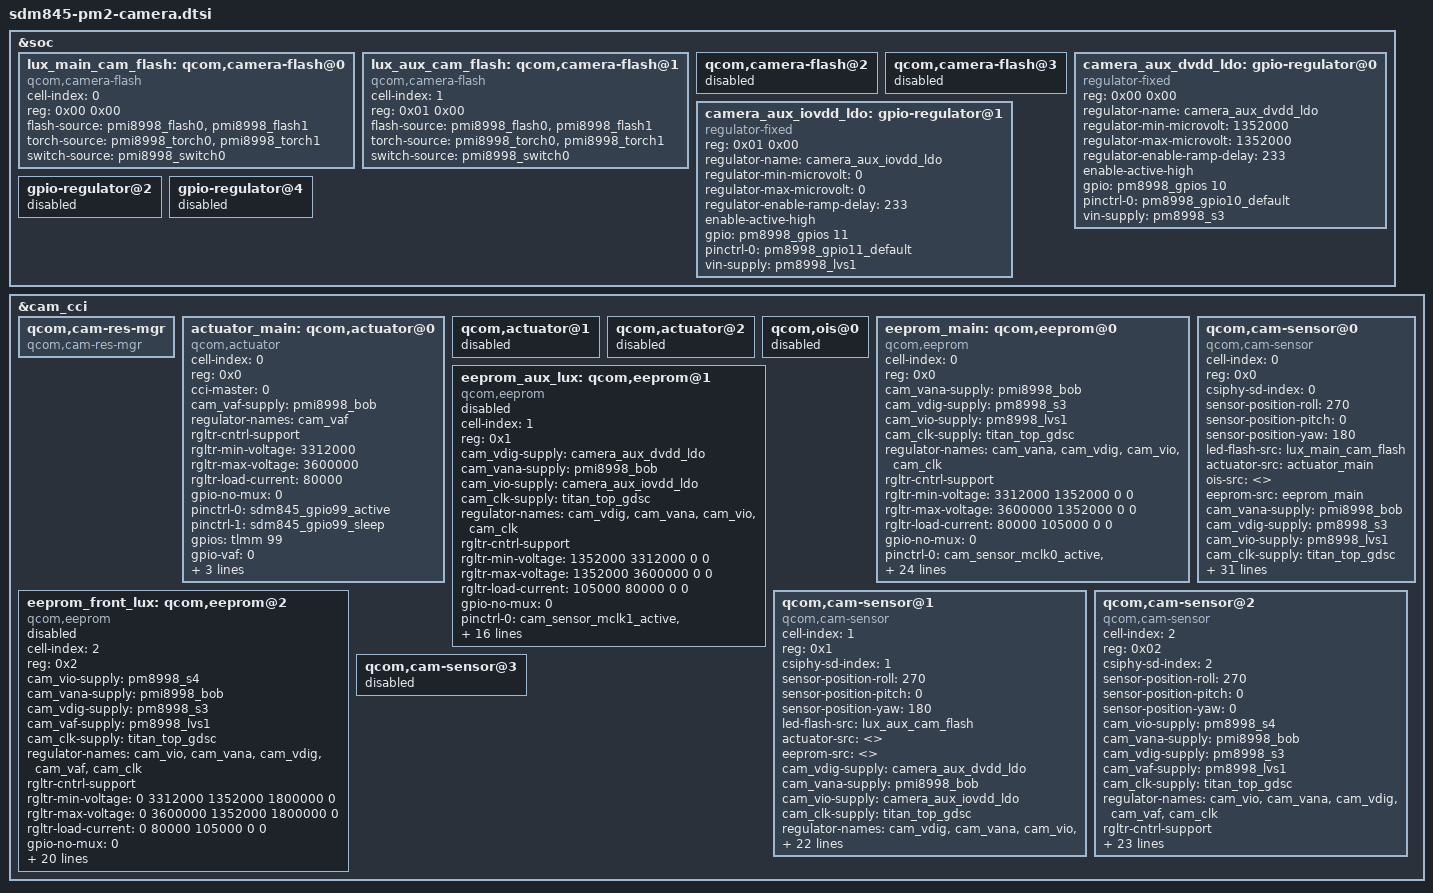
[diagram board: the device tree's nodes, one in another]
/*
 * Copyright (c) 2016-2018, The Linux Foundation. All rights reserved.
 *
 * This program is free software; you can redistribute it and/or modify
 * it under the terms of the GNU General Public License version 2 and
 * only version 2 as published by the Free Software Foundation.
 *
 * This program is distributed in the hope that it will be useful,
 * but WITHOUT ANY WARRANTY; without even the implied warranty of
 * MERCHANTABILITY or FITNESS FOR A PARTICULAR PURPOSE.  See the
 * GNU General Public License for more details.
 */

&soc {
	lux_main_cam_flash: qcom,camera-flash@0 {
		cell-index = <0>;
		reg = <0x00 0x00>;
		compatible = "qcom,camera-flash";
		flash-source = <&pmi8998_flash0 &pmi8998_flash1>;
		torch-source = <&pmi8998_torch0 &pmi8998_torch1>;
		switch-source = <&pmi8998_switch0>;
		status = "ok";
	};

	lux_aux_cam_flash: qcom,camera-flash@1 {
		cell-index = <1>;
		reg = <0x01 0x00>;
		compatible = "qcom,camera-flash";
		flash-source = <&pmi8998_flash0 &pmi8998_flash1>;
		torch-source = <&pmi8998_torch0 &pmi8998_torch1>;
		switch-source = <&pmi8998_switch0>;
		status = "ok";
	};

	qcom,camera-flash@2 {
		status = "disabled";
	};

	qcom,camera-flash@3 {
		status = "disabled";
	};

	camera_aux_dvdd_ldo: gpio-regulator@0 {
		compatible = "regulator-fixed";
		reg = <0x00 0x00>;
		regulator-name = "camera_aux_dvdd_ldo";
		regulator-min-microvolt = <1352000>;
		regulator-max-microvolt = <1352000>;
		regulator-enable-ramp-delay = <233>;
		enable-active-high;
		gpio = <&pm8998_gpios 10 0>;
		pinctrl-names = "default";
		pinctrl-0 = <&pm8998_gpio10_default>;
		vin-supply = <&pm8998_s3>;
	};

	camera_aux_iovdd_ldo: gpio-regulator@1 {
		compatible = "regulator-fixed";
		reg = <0x01 0x00>;
		regulator-name = "camera_aux_iovdd_ldo";
		regulator-min-microvolt = <0>;
		regulator-max-microvolt = <0>;
		regulator-enable-ramp-delay = <233>;
		enable-active-high;
		gpio = <&pm8998_gpios 11 0>;
		pinctrl-names = "default";
		pinctrl-0 = <&pm8998_gpio11_default>;
		vin-supply = <&pm8998_lvs1>; /*use for i2c pull up*/
	};

	gpio-regulator@2 {
		status = "disabled";
	};

	gpio-regulator@4 {
		status = "disabled";
	};
};

&cam_cci {
	qcom,cam-res-mgr {
		compatible = "qcom,cam-res-mgr";
		status = "ok";
	};

	actuator_main: qcom,actuator@0 {
		cell-index = <0>;
		reg = <0x0>;
		compatible = "qcom,actuator";
		cci-master = <0>;
		cam_vaf-supply = <&pmi8998_bob>;
		regulator-names = "cam_vaf";
		rgltr-cntrl-support;
		rgltr-min-voltage = <3312000>;
		rgltr-max-voltage = <3600000>;
		rgltr-load-current = <80000>;
		gpio-no-mux = <0>;
		pinctrl-names = "cam_default", "cam_suspend";
		pinctrl-0 = <&sdm845_gpio99_active>;
		pinctrl-1 = <&sdm845_gpio99_sleep>;
		gpios = <&tlmm 99 0>;
		gpio-vaf = <0>;
		gpio-req-tbl-num = <0>;
		gpio-req-tbl-flags = <0>;
		gpio-req-tbl-label = "CAM_VAF0";
	};

	qcom,actuator@1 {
		status = "disabled";
	};

	qcom,actuator@2 {
		status = "disabled";
	};

	qcom,ois@0 {
		status = "disabled";
	};

	eeprom_main: qcom,eeprom@0 {
		cell-index = <0>;
		reg = <0x0>;
		compatible = "qcom,eeprom";
		cam_vana-supply = <&pmi8998_bob>;
		cam_vdig-supply = <&pm8998_s3>;
		cam_vio-supply = <&pm8998_lvs1>; /* for i2c pull-up voltage */
		cam_clk-supply = <&titan_top_gdsc>;
		regulator-names = "cam_vana", "cam_vdig", "cam_vio",
			"cam_clk";
		rgltr-cntrl-support;
		rgltr-min-voltage = <3312000 1352000 0 0>;
		rgltr-max-voltage = <3600000 1352000 0 0>;
		rgltr-load-current = <80000 105000 0 0>;
		gpio-no-mux = <0>;
		pinctrl-names = "cam_default", "cam_suspend";
		pinctrl-0 = <&cam_sensor_mclk0_active
				&sdm845_gpio30_active
				&sdm845_gpio100_active
				&sdm845_gpio91_active
				&sdm845_gpio25_active
				&sdm845_gpio51_active>;
		pinctrl-1 = <&cam_sensor_mclk0_suspend
				&sdm845_gpio30_sleep
				&sdm845_gpio100_sleep
				&sdm845_gpio91_sleep
				&sdm845_gpio25_sleep
				&sdm845_gpio51_sleep>;
		gpios = <&tlmm 13 0>,
			<&tlmm 30 0>,
			<&tlmm 100 0>,
			<&tlmm 91 0>,
			<&tlmm 25 0>,
			<&tlmm 51 0>;
		gpio-reset = <1>;
		gpio-vana = <2>;
		gpio-vdig = <3>;
		gpio-vio = <4>;
		gpio-custom1 = <5>;
		gpio-req-tbl-num = <0 1 2 3 4 5>;
		gpio-req-tbl-flags = <1 0 0 0 0 0>;
		gpio-req-tbl-label = "CAMIF_MCLK0",
					"CAM_RESET0",
					"CAM_VANA0",
					"CAM_VDIG0",
					"CAM_VIO0",
					"CAM_CUSTOM0";
		sensor-position = <0>;
		sensor-mode = <0>;
		cci-master = <0>;
		status = "ok";
		clocks = <&clock_camcc CAM_CC_MCLK0_CLK>;
		clock-names = "cam_clk";
		clock-cntl-level = "turbo";
		clock-rates = <24000000>;
	};

	eeprom_aux_lux: qcom,eeprom@1 {
		cell-index = <1>;
		reg = <0x1>;
		compatible = "qcom,eeprom";
		cam_vdig-supply = <&camera_aux_dvdd_ldo>;
		cam_vana-supply = <&pmi8998_bob>;
		cam_vio-supply = <&camera_aux_iovdd_ldo>;
		cam_clk-supply = <&titan_top_gdsc>;
		regulator-names = "cam_vdig", "cam_vana", "cam_vio", "cam_clk";
		rgltr-cntrl-support;
		rgltr-min-voltage = <1352000 3312000 0 0>;
		rgltr-max-voltage = <1352000 3600000 0 0>;
		rgltr-load-current = <105000 80000 0 0>;
		gpio-no-mux = <0>;
		pinctrl-names = "cam_default", "cam_suspend";
		pinctrl-0 = <&cam_sensor_mclk1_active
				&sdm845_gpio80_active>;
		pinctrl-1 = <&cam_sensor_mclk1_suspend
				&sdm845_gpio80_sleep>;
		gpios = <&tlmm 14 0>,
			<&tlmm 80 0>,
			<&pm8998_gpios 12 0>;
		gpio-reset = <1>;
		gpio-vana = <2>;
		gpio-req-tbl-num = <0 1 2>;
		gpio-req-tbl-flags = <1 0 0>;
		gpio-req-tbl-label = "CAMIF_MCLK1",
					"CAM_RESET1",
					"CAM_VANA1";
		sensor-position = <0>;
		sensor-mode = <0>;
		cci-master = <1>;
		status = "disabled";
		clocks = <&clock_camcc CAM_CC_MCLK1_CLK>;
		clock-names = "cam_clk";
		clock-cntl-level = "turbo";
		clock-rates = <23076923>;
	};

	eeprom_front_lux: qcom,eeprom@2 {
		cell-index = <2>;
		reg = <0x2>;
		compatible = "qcom,eeprom";
		cam_vio-supply = <&pm8998_s4>;
		cam_vana-supply = <&pmi8998_bob>;
		cam_vdig-supply = <&pm8998_s3>;
		cam_vaf-supply = <&pm8998_lvs1>;
		cam_clk-supply = <&titan_top_gdsc>;
		regulator-names = "cam_vio", "cam_vana", "cam_vdig","cam_vaf",
			"cam_clk";
		rgltr-cntrl-support;
		rgltr-min-voltage = <0 3312000 1352000 1800000 0>;
		rgltr-max-voltage = <0 3600000 1352000 1800000 0>;
		rgltr-load-current = <0 80000 105000 0 0>;
		gpio-no-mux = <0>;
		pinctrl-names = "cam_default", "cam_suspend";
		pinctrl-0 = <&cam_sensor_mclk2_active
				 &sdm845_gpio9_active>;
		pinctrl-1 = <&cam_sensor_mclk2_suspend
				 &sdm845_gpio9_sleep>;
		gpios = <&tlmm 15 0>,
			<&tlmm 9 0>,
			<&pm8998_gpios 7 0>,
			<&pm8998_gpios 8 0>,
			<&pm8998_gpios 4 0>;
		gpio-reset = <1>;
		gpio-vana = <2>;
		gpio-vio = <3>;
		gpio-vdig = <4>;
		gpio-req-tbl-num = <0 1 2 3 4>;
		gpio-req-tbl-flags = <1 0 0 0 0>;
		gpio-req-tbl-label = "CAMIF_MCLK2",
					"CAM_RESET2",
					"CAM_VANA2",
					"CAM_VIO2",
					"CAM_VDIG2";
		sensor-position = <1>;
		sensor-mode = <0>;
		cci-master = <1>;
		status = "disabled";
		clocks = <&clock_camcc CAM_CC_MCLK2_CLK>;
		clock-names = "cam_clk";
		clock-cntl-level = "turbo";
		clock-rates = <24000000>;
	};

	qcom,cam-sensor@0 {
		cell-index = <0>;
		compatible = "qcom,cam-sensor";
		reg = <0x0>;
		csiphy-sd-index = <0>;
		sensor-position-roll = <270>;
		sensor-position-pitch = <0>;
		sensor-position-yaw = <180>;
		led-flash-src = <&lux_main_cam_flash>;
		actuator-src = <&actuator_main>;
		ois-src = <>;
		eeprom-src = <&eeprom_main>;
		cam_vana-supply = <&pmi8998_bob>;
		cam_vdig-supply = <&pm8998_s3>;
		cam_vio-supply = <&pm8998_lvs1>; /* for i2c pull-up voltage */
		cam_clk-supply = <&titan_top_gdsc>;
		regulator-names = "cam_vana", "cam_vdig", "cam_vio",
			"cam_clk";
		rgltr-cntrl-support;
		rgltr-min-voltage = <3312000 1352000 0 0>;
		rgltr-max-voltage = <3600000 1352000 0 0>;
		rgltr-load-current = <80000 105000 0 0>;
		gpio-no-mux = <0>;
		pinctrl-names = "cam_default", "cam_suspend";
		pinctrl-0 = <&cam_sensor_mclk0_active
				&sdm845_gpio30_active
				&sdm845_gpio100_active
				&sdm845_gpio91_active
				&sdm845_gpio25_active
				&sdm845_gpio51_active>;
		pinctrl-1 = <&cam_sensor_mclk0_suspend
				&sdm845_gpio30_sleep
				&sdm845_gpio100_sleep
				&sdm845_gpio91_sleep
				&sdm845_gpio25_sleep
				&sdm845_gpio51_sleep>;
		gpios = <&tlmm 13 0>,
			<&tlmm 30 0>,
			<&tlmm 100 0>,
			<&tlmm 91 0>,
			<&tlmm 25 0>,
			<&tlmm 51 0>;
		gpio-reset = <1>;
		gpio-vana = <2>;
		gpio-vdig = <3>;
		gpio-vio = <4>;
		gpio-custom1 = <5>;
		gpio-req-tbl-num = <0 1 2 3 4 5>;
		gpio-req-tbl-flags = <1 0 0 0 0 0>;
		gpio-req-tbl-label = "CAMIF_MCLK0",
					"CAM_RESET0",
					"CAM_VANA0",
					"CAM_VDIG0",
					"CAM_VIO0",
					"CAM_CUSTOM0";
		sensor-mode = <0>;
		cci-master = <0>;
		status = "ok";
		clocks = <&clock_camcc CAM_CC_MCLK0_CLK>;
		clock-names = "cam_clk";
		clock-cntl-level = "turbo";
		clock-rates = <24000000>;
	};

	qcom,cam-sensor@1 {
		cell-index = <1>;
		compatible = "qcom,cam-sensor";
		reg = <0x1>;
		csiphy-sd-index = <1>;
		sensor-position-roll = <270>;
		sensor-position-pitch = <0>;
		sensor-position-yaw = <180>;
		led-flash-src = <&lux_aux_cam_flash>;
		actuator-src = <>;
		eeprom-src = <>;
		/*eeprom-src = <&eeprom_aux_lux>;*/
		cam_vdig-supply = <&camera_aux_dvdd_ldo>;
		cam_vana-supply = <&pmi8998_bob>;
		cam_vio-supply = <&camera_aux_iovdd_ldo>;
		cam_clk-supply = <&titan_top_gdsc>;
		regulator-names = "cam_vdig", "cam_vana", "cam_vio", "cam_clk";
		rgltr-cntrl-support;
		rgltr-min-voltage = <1352000 3312000 0 0>;
		rgltr-max-voltage = <1352000 3600000 0 0>;
		rgltr-load-current = <105000 80000 0 0>;
		gpio-no-mux = <0>;
		pinctrl-names = "cam_default", "cam_suspend";
		pinctrl-0 = <&cam_sensor_mclk1_active
				&sdm845_gpio80_active>;
		pinctrl-1 = <&cam_sensor_mclk1_suspend
				&sdm845_gpio80_sleep>;
		gpios = <&tlmm 14 0>,
			<&tlmm 80 0>,
			<&pm8998_gpios 12 0>;
		gpio-reset = <1>;
		gpio-vana = <2>;
		gpio-req-tbl-num = <0 1 2>;
		gpio-req-tbl-flags = <1 0 0>;
		gpio-req-tbl-label = "CAMIF_MCLK1",
					"CAM_RESET1",
					"CAM_VANA1";
		sensor-mode = <0>;
		cci-master = <1>;
		status = "ok";
		clocks = <&clock_camcc CAM_CC_MCLK1_CLK>;
		clock-names = "cam_clk";
		clock-cntl-level = "turbo";
		clock-rates = <23076923>;
	};

	qcom,cam-sensor@2 {
		cell-index = <2>;
		compatible = "qcom,cam-sensor";
		reg = <0x02>;
		csiphy-sd-index = <2>;
		sensor-position-roll = <270>;
		sensor-position-pitch = <0>;
		sensor-position-yaw = <0>;
		/*eeprom-src = <&eeprom_front_lux>;*/
		cam_vio-supply = <&pm8998_s4>;
		cam_vana-supply = <&pmi8998_bob>;
		cam_vdig-supply = <&pm8998_s3>;
		cam_vaf-supply = <&pm8998_lvs1>;
		cam_clk-supply = <&titan_top_gdsc>;
		regulator-names = "cam_vio", "cam_vana", "cam_vdig","cam_vaf",
			"cam_clk";
		rgltr-cntrl-support;
		rgltr-min-voltage = <0 3312000 1352000 1800000 0>;
		rgltr-max-voltage = <0 3600000 1352000 1800000 0>;
		rgltr-load-current = <0 80000 105000 0 0>;
		gpio-no-mux = <0>;
		pinctrl-names = "cam_default", "cam_suspend";
		pinctrl-0 = <&cam_sensor_mclk2_active
				 &sdm845_gpio9_active>;
		pinctrl-1 = <&cam_sensor_mclk2_suspend
				 &sdm845_gpio9_sleep>;
		gpios = <&tlmm 15 0>,
			<&tlmm 9 0>,
			<&pm8998_gpios 7 0>,
			<&pm8998_gpios 8 0>,
			<&pm8998_gpios 4 0>;
		gpio-reset = <1>;
		gpio-vana = <2>;
		gpio-vio = <3>;
		gpio-vdig = <4>;
		gpio-req-tbl-num = <0 1 2 3 4>;
		gpio-req-tbl-flags = <1 0 0 0 0>;
		gpio-req-tbl-label = "CAMIF_MCLK2",
					"CAM_RESET2",
					"CAM_VANA2",
					"CAM_VIO2",
					"CAM_VDIG2";
		sensor-mode = <0>;
		cci-master = <1>;
		status = "ok";
		clocks = <&clock_camcc CAM_CC_MCLK2_CLK>;
		clock-names = "cam_clk";
		clock-cntl-level = "turbo";
		clock-rates = <24000000>;
	};

	qcom,cam-sensor@3 {
		status = "disabled";
	};
};
